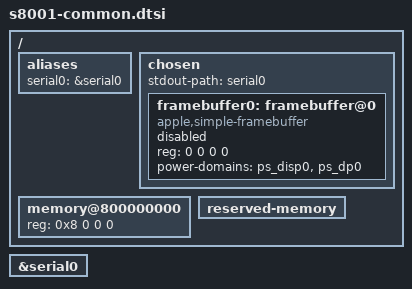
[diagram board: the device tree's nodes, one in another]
// SPDX-License-Identifier: GPL-2.0+ OR MIT
/*
 * Apple iPad Pro (9.7-inch), iPad Pro (12.9-inch)
 *
 * This file contains parts common to all Apple A9X devices.
 *
 * target-type: J127, J128, J98a, J99a
 *
 * Copyright (c) 2024, Nick Chan <towinchenmi@gmail.com>
 */

/ {
	aliases {
		serial0 = &serial0;
	};

	chosen {
		#address-cells = <2>;
		#size-cells = <2>;
		ranges;

		stdout-path = "serial0";

		framebuffer0: framebuffer@0 {
			compatible = "apple,simple-framebuffer", "simple-framebuffer";
			reg = <0 0 0 0>; /* To be filled by loader */
			power-domains = <&ps_disp0 &ps_dp0>;
			/* Format properties will be added by loader */
			status = "disabled";
		};
	};

	memory@800000000 {
		device_type = "memory";
		reg = <0x8 0 0 0>; /* To be filled by loader */
	};

	reserved-memory {
		#address-cells = <2>;
		#size-cells = <2>;
		ranges;

		/* To be filled by loader */
	};
};

&serial0 {
	status = "okay";
};
